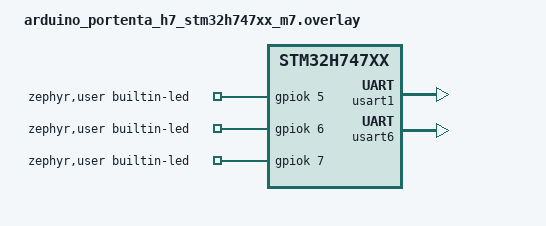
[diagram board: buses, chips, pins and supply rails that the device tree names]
/ {
	chosen {
		zephyr,console = &usart6;
		zephyr,shell-uart = &usart6;
		zephyr,cdc-acm-uart0 = &usart6;
		uart,passthrough = &usart1; // Teensy pins 7(RX) 8(TX)
	};
};

/ {
	zephyr,user {
		builtin-led-gpios = <&gpiok 5 0>,
				    <&gpiok 6 0>,
				    <&gpiok 7 0>;

	};
};

&usart1 {
	status = "okay";
};


&usart6 {
	status = "okay";
};

